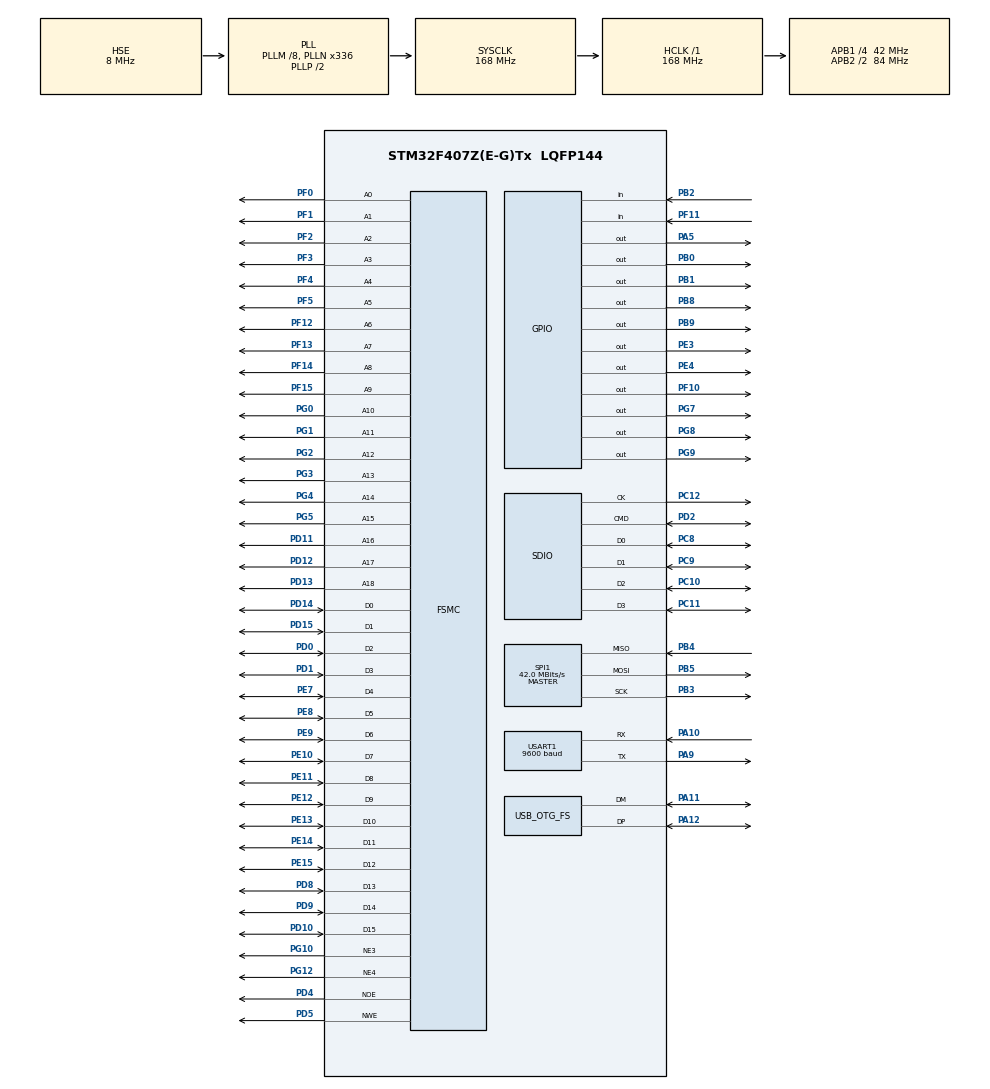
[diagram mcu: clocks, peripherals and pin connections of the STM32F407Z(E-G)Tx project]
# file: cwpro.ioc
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Dma.Request0=SDIO_RX
Dma.Request1=SDIO_TX
Dma.SDIO_RX.0.Direction=DMA_PERIPH_TO_MEMORY
Dma.SDIO_RX.0.FIFOMode=DMA_FIFOMODE_ENABLE
Dma.SDIO_RX.0.FIFOThreshold=DMA_FIFO_THRESHOLD_FULL
Dma.SDIO_RX.0.Instance=DMA2_Stream3
Dma.SDIO_RX.0.MemBurst=DMA_MBURST_INC4
Dma.SDIO_RX.0.MemDataAlignment=DMA_MDATAALIGN_WORD
Dma.SDIO_RX.0.MemInc=DMA_MINC_ENABLE
Dma.SDIO_RX.0.Mode=DMA_PFCTRL
Dma.SDIO_RX.0.PeriphBurst=DMA_PBURST_INC4
Dma.SDIO_RX.0.PeriphDataAlignment=DMA_PDATAALIGN_WORD
Dma.SDIO_RX.0.PeriphInc=DMA_PINC_DISABLE
Dma.SDIO_RX.0.Priority=DMA_PRIORITY_LOW
Dma.SDIO_TX.1.Direction=DMA_MEMORY_TO_PERIPH
Dma.SDIO_TX.1.FIFOMode=DMA_FIFOMODE_ENABLE
Dma.SDIO_TX.1.FIFOThreshold=DMA_FIFO_THRESHOLD_FULL
Dma.SDIO_TX.1.Instance=DMA2_Stream6
Dma.SDIO_TX.1.MemBurst=DMA_MBURST_INC4
Dma.SDIO_TX.1.MemDataAlignment=DMA_MDATAALIGN_WORD
Dma.SDIO_TX.1.MemInc=DMA_MINC_ENABLE
Dma.SDIO_TX.1.Mode=DMA_PFCTRL
Dma.SDIO_TX.1.PeriphBurst=DMA_PBURST_INC4
Dma.SDIO_TX.1.PeriphDataAlignment=DMA_PDATAALIGN_WORD
Dma.SDIO_TX.1.PeriphInc=DMA_PINC_DISABLE
Dma.SDIO_TX.1.Priority=DMA_PRIORITY_LOW
FATFS._CODE_PAGE=936
FATFS._USE_LFN=2
FREERTOS.Queues01=myQueue01,16,uint16_t,0,Dynamic,NULL,NULL
FREERTOS.Tasks01=defaultTask,0,1024,StartDefaultTask,Default,NULL,Dynamic,NULL,NULL;Task_touch,-2,1024,StartTask_touch,Default,NULL,Dynamic,NULL,NULL;Task_main,0,3072,StartTask_main,Default,NULL,Dynamic,NULL,NULL
FREERTOS.configMINIMAL_STACK_SIZE=128
FREERTOS.configTOTAL_HEAP_SIZE=0x5c00
FSMC.AddressSetupTime1=0
FSMC.BusTurnAroundDuration1=0
FSMC.BusTurnAroundDuration2=0
FSMC.DataSetupTime1=0x0b
FSMC.DataSetupTime2=60
FSMC.ExtendedAddressSetupTime2=8
FSMC.ExtendedBusTurnAroundDuration2=0
FSMC.ExtendedDataSetupTime2=7
FSMC.ExtendedMode2=FSMC_EXTENDED_MODE_ENABLE
FSMC.WriteOperation1=FSMC_WRITE_OPERATION_ENABLE
Mcu.Family=STM32F4
Mcu.Name=STM32F407Z(E-G)Tx
Mcu.Package=LQFP144
NVIC.DMA2_Stream3_IRQn=true\:5\:0\:true\:false\:true\:true\:false\:true\:true
NVIC.DMA2_Stream6_IRQn=true\:5\:0\:true\:false\:true\:true\:false\:true\:true
NVIC.HASH_RNG_IRQn=true\:5\:0\:false\:false\:true\:true\:true\:true\:true
NVIC.OTG_FS_IRQn=true\:5\:0\:false\:false\:true\:true\:false\:true\:true
NVIC.PriorityGroup=NVIC_PRIORITYGROUP_4
NVIC.SDIO_IRQn=true\:5\:0\:false\:false\:true\:true\:true\:true\:true
PA10.Mode=Asynchronous
PA10.Signal=USART1_RX
PA11.Mode=Host_Only
PA11.Signal=USB_OTG_FS_DM
PA12.Mode=Host_Only
PA12.Signal=USB_OTG_FS_DP
PA13.Mode=Serial_Wire
PA13.Signal=SYS_JTMS-SWDIO
PA14.Mode=Serial_Wire
PA14.Signal=SYS_JTCK-SWCLK
PA5.GPIO_PuPd=GPIO_PULLUP
PA5.Signal=GPIO_Output
PA9.Mode=Asynchronous
PA9.Signal=USART1_TX
PB0.GPIO_ModeDefaultOutputPP=GPIO_MODE_OUTPUT_PP
PB0.GPIO_PuPd=GPIO_PULLUP
PB0.Signal=GPIO_Output
PB1.GPIO_PuPd=GPIO_PULLUP
PB1.Signal=GPIO_Output
PB2.GPIO_PuPd=GPIO_PULLUP
PB2.Signal=GPIO_Input
PB3.Mode=Full_Duplex_Master
PB3.Signal=SPI1_SCK
PB4.Mode=Full_Duplex_Master
PB4.Signal=SPI1_MISO
PB5.Mode=Full_Duplex_Master
PB5.Signal=SPI1_MOSI
PB8.GPIO_PuPd=GPIO_PULLUP
PB8.Signal=GPIO_Output
PB9.GPIO_PuPd=GPIO_PULLUP
PB9.Signal=GPIO_Output
PC10.GPIO_PuPd=GPIO_PULLUP
PC10.Mode=SD_4_bits_Wide_bus
PC10.Signal=SDIO_D2
PC11.GPIO_PuPd=GPIO_PULLUP
PC11.Mode=SD_4_bits_Wide_bus
PC11.Signal=SDIO_D3
PC12.GPIO_PuPd=GPIO_PULLUP
PC12.Mode=SD_4_bits_Wide_bus
PC12.Signal=SDIO_CK
PC8.GPIO_PuPd=GPIO_PULLUP
PC8.Mode=SD_4_bits_Wide_bus
PC8.Signal=SDIO_D0
PC9.GPIO_PuPd=GPIO_PULLUP
PC9.Mode=SD_4_bits_Wide_bus
PC9.Signal=SDIO_D1
PD0.Signal=FSMC_D2_DA2
PD1.Signal=FSMC_D3_DA3
PD10.Signal=FSMC_D15_DA15
PD11.Signal=FSMC_A16_CLE
PD12.Signal=FSMC_A17_ALE
PD13.Signal=FSMC_A18
PD14.Signal=FSMC_D0_DA0
PD15.Signal=FSMC_D1_DA1
PD2.GPIO_PuPd=GPIO_PULLUP
PD2.Mode=SD_4_bits_Wide_bus
PD2.Signal=SDIO_CMD
PD4.Signal=FSMC_NOE
PD5.Signal=FSMC_NWE
PD8.Signal=FSMC_D13_DA13
PD9.Signal=FSMC_D14_DA14
PE0.Signal=FSMC_NBL0
PE1.Signal=FSMC_NBL1
PE10.Signal=FSMC_D7_DA7
PE11.Signal=FSMC_D8_DA8
PE12.Signal=FSMC_D9_DA9
PE13.Signal=FSMC_D10_DA10
PE14.Signal=FSMC_D11_DA11
PE15.Signal=FSMC_D12_DA12
PE3.GPIO_PuPd=GPIO_PULLUP
PE3.Signal=GPIO_Output
PE4.GPIO_PuPd=GPIO_PULLUP
PE4.Signal=GPIO_Output
PE7.Signal=FSMC_D4_DA4
PE8.Signal=FSMC_D5_DA5
PE9.Signal=FSMC_D6_DA6
PF0.Signal=FSMC_A0
PF1.Signal=FSMC_A1
PF10.GPIO_PuPd=GPIO_PULLUP
PF10.Signal=GPIO_Output
PF11.GPIO_PuPd=GPIO_PULLUP
PF11.Signal=GPIO_Input
PF12.Signal=FSMC_A6
PF13.Signal=FSMC_A7
PF14.Signal=FSMC_A8
PF15.Signal=FSMC_A9
PF2.Signal=FSMC_A2
PF3.Signal=FSMC_A3
PF4.Signal=FSMC_A4
PF5.Signal=FSMC_A5
PG0.Signal=FSMC_A10
PG1.Signal=FSMC_A11
PG10.Mode=NorPsramChipSelect3_1
PG10.Signal=FSMC_NE3
PG12.Mode=NorPsramChipSelect4_2
PG12.Signal=FSMC_NE4
PG2.Signal=FSMC_A12
PG3.Signal=FSMC_A13
PG4.Signal=FSMC_A14
PG5.Signal=FSMC_A15
PG7.GPIO_PuPd=GPIO_PULLUP
PG7.Signal=GPIO_Output
PG8.GPIO_PuPd=GPIO_PULLUP
PG8.Signal=GPIO_Output
PG9.GPIO_PuPd=GPIO_PULLUP
PG9.Signal=GPIO_Output
PH0-OSC_IN.Mode=HSE-External-Oscillator
PH0-OSC_IN.Signal=RCC_OSC_IN
PH1-OSC_OUT.Mode=HSE-External-Oscillator
PH1-OSC_OUT.Signal=RCC_OSC_OUT
ProjectManager.HeapSize=0xf00
ProjectManager.StackSize=0xf00
ProjectManager.TargetToolchain=MDK-ARM V5.32
RCC.48MHZClocksFreq_Value=48000000
RCC.AHBFreq_Value=168000000
RCC.APB1CLKDivider=RCC_HCLK_DIV4
RCC.APB1Freq_Value=42000000
RCC.APB1TimFreq_Value=84000000
RCC.APB2CLKDivider=RCC_HCLK_DIV2
RCC.APB2Freq_Value=84000000
RCC.APB2TimFreq_Value=168000000
RCC.CortexFreq_Value=168000000
RCC.HCLKFreq_Value=168000000
RCC.HSE_VALUE=8000000
RCC.HSI_VALUE=16000000
RCC.LSE_VALUE=32768
RCC.PLLM=8
RCC.PLLN=336
RCC.PLLQ=7
RCC.SYSCLKFreq_VALUE=168000000
RCC.SYSCLKSource=RCC_SYSCLKSOURCE_PLLCLK
RCC.VCOOutputFreq_Value=336000000
SDIO.ClockDiv=4
SH.FSMC_A0.0=FSMC_A0,19b-a1
SH.FSMC_A1.0=FSMC_A1,19b-a1
SH.FSMC_A10.0=FSMC_A10,19b-a1
SH.FSMC_A11.0=FSMC_A11,19b-a1
SH.FSMC_A12.0=FSMC_A12,19b-a1
SH.FSMC_A12.1=FSMC_A12,A12_2
SH.FSMC_A13.0=FSMC_A13,19b-a1
SH.FSMC_A14.0=FSMC_A14,19b-a1
SH.FSMC_A15.0=FSMC_A15,19b-a1
SH.FSMC_A16_CLE.0=FSMC_A16,19b-a1
SH.FSMC_A17_ALE.0=FSMC_A17,19b-a1
SH.FSMC_A18.0=FSMC_A18,19b-a1
SH.FSMC_A2.0=FSMC_A2,19b-a1
SH.FSMC_A3.0=FSMC_A3,19b-a1
SH.FSMC_A4.0=FSMC_A4,19b-a1
SH.FSMC_A5.0=FSMC_A5,19b-a1
SH.FSMC_A6.0=FSMC_A6,19b-a1
SH.FSMC_A7.0=FSMC_A7,19b-a1
SH.FSMC_A8.0=FSMC_A8,19b-a1
SH.FSMC_A9.0=FSMC_A9,19b-a1
SH.FSMC_D0_DA0.0=FSMC_D0,16b-d1
SH.FSMC_D0_DA0.1=FSMC_D0,16b-d2
SH.FSMC_D10_DA10.0=FSMC_D10,16b-d1
SH.FSMC_D10_DA10.1=FSMC_D10,16b-d2
SH.FSMC_D11_DA11.0=FSMC_D11,16b-d1
SH.FSMC_D11_DA11.1=FSMC_D11,16b-d2
SH.FSMC_D12_DA12.0=FSMC_D12,16b-d1
SH.FSMC_D12_DA12.1=FSMC_D12,16b-d2
SH.FSMC_D13_DA13.0=FSMC_D13,16b-d1
SH.FSMC_D13_DA13.1=FSMC_D13,16b-d2
SH.FSMC_D14_DA14.0=FSMC_D14,16b-d1
SH.FSMC_D14_DA14.1=FSMC_D14,16b-d2
SH.FSMC_D15_DA15.0=FSMC_D15,16b-d1
SH.FSMC_D15_DA15.1=FSMC_D15,16b-d2
SH.FSMC_D1_DA1.0=FSMC_D1,16b-d1
SH.FSMC_D1_DA1.1=FSMC_D1,16b-d2
SH.FSMC_D2_DA2.0=FSMC_D2,16b-d1
SH.FSMC_D2_DA2.1=FSMC_D2,16b-d2
SH.FSMC_D3_DA3.0=FSMC_D3,16b-d1
SH.FSMC_D3_DA3.1=FSMC_D3,16b-d2
SH.FSMC_D4_DA4.0=FSMC_D4,16b-d1
SH.FSMC_D4_DA4.1=FSMC_D4,16b-d2
SH.FSMC_D5_DA5.0=FSMC_D5,16b-d1
SH.FSMC_D5_DA5.1=FSMC_D5,16b-d2
SH.FSMC_D6_DA6.0=FSMC_D6,16b-d1
SH.FSMC_D6_DA6.1=FSMC_D6,16b-d2
SH.FSMC_D7_DA7.0=FSMC_D7,16b-d1
SH.FSMC_D7_DA7.1=FSMC_D7,16b-d2
SH.FSMC_D8_DA8.0=FSMC_D8,16b-d1
SH.FSMC_D8_DA8.1=FSMC_D8,16b-d2
SH.FSMC_D9_DA9.0=FSMC_D9,16b-d1
SH.FSMC_D9_DA9.1=FSMC_D9,16b-d2
SH.FSMC_NBL0.0=FSMC_NBL0
SH.FSMC_NBL1.0=FSMC_NBL1
SH.FSMC_NOE.0=FSMC_NOE,Sram1
SH.FSMC_NOE.1=FSMC_NOE,Lcd2
SH.FSMC_NWE.0=FSMC_NWE,Sram1
SH.FSMC_NWE.1=FSMC_NWE,Lcd2
SPI1.CalculateBaudRate=42.0 MBits/s
SPI1.Direction=SPI_DIRECTION_2LINES
SPI1.Mode=SPI_MODE_MASTER
SPI1.VirtualType=VM_MASTER
USART1.BaudRate=9600
USART1.VirtualMode=VM_ASYNC
USB_HOST.USBH_DEBUG_LEVEL-MSC_FS=2
USB_HOST.USBH_HandleTypeDef-MSC_FS=hUsbHostFS
USB_HOST.USBH_PROCESS_STACK_SIZE-MSC_FS=512
USB_HOST.VirtualModeFS=Msc
USB_OTG_FS.VirtualMode=Host_Only
USB_OTG_FS.phy_itface=HCD_PHY_EMBEDDED
VP_CRC_VS_CRC.Mode=CRC_Activate
VP_FATFS_VS_SDIO.Mode=SDIO
VP_FATFS_VS_USB.Mode=USB
VP_FREERTOS_VS_CMSIS_V1.Mode=CMSIS_V1
VP_RNG_VS_RNG.Mode=RNG_Activate
VP_USB_HOST_VS_USB_HOST_MSC_FS.Mode=MSC_FS
board=custom

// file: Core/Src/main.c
/* USER CODE BEGIN Header */
/**
  ******************************************************************************
  * @file           : main.c
  * @brief          : Main program body
  ******************************************************************************
  * @attention
  *
  * Copyright (c) 2023 STMicroelectronics.
  * All rights reserved.
  *
  * This software is licensed under terms that can be found in the LICENSE file
  * in the root directory of this software component.
  * If no LICENSE file comes with this software, it is provided AS-IS.
  *
  ******************************************************************************
  */
/* USER CODE END Header */
#include "main.h"
#include "cmsis_os.h"
#include "crc.h"
#include "dma.h"
#include "fatfs.h"
#include "rng.h"
#include "sdio.h"
#include "spi.h"
#include "usart.h"
#include "usb_host.h"
#include "gpio.h"
#include "fsmc.h"

/* USER CODE BEGIN Includes */
#include "malloc.h"
#include "touch.h"
#include "common.h"

/* USER CODE END Includes */

/* USER CODE BEGIN PV */
 uint32_t g_sys_status = SYS_IDLE;//SYS_IDLE;

 uint32_t g_DiskStatus = NO_DISK_INSERTED;

 uint32_t g_rand[256];
/* USER CODE END PV */

void SystemClock_Config(void);
void MX_FREERTOS_Init(void);

int main(void)
{
  /* USER CODE BEGIN 1 */
    FATFS fsTF;  //TF卡文件系统
	int ret;
  /* USER CODE END 1 */

  /* MCU Configuration--------------------------------------------------------*/

  /* Reset of all peripherals, Initializes the Flash interface and the Systick. */
  HAL_Init();

  /* Configure the system clock */
  SystemClock_Config();

  /* Initialize all configured peripherals */
  MX_GPIO_Init();
  MX_DMA_Init();
  MX_FSMC_Init();
  MX_USART1_UART_Init();
  MX_CRC_Init();
  MX_FATFS_Init();
  MX_SDIO_SD_Init();
  MX_SPI1_Init();
  MX_RNG_Init();
  /* USER CODE BEGIN 2 */
	printf("hello world!!!!\r\n");

 // Memory_Init(INSRAM); 		//初始化内部内存池
 //Memory_Init(EXSRAM);  	//初始化外部内存池
 //  ret = f_mount(&fsTF,"0:",1); 		//挂载TF卡
	//printf("hello Memory_Init succ!!!! ret=%d\r\n",ret);
  /* USER CODE END 2 */

  /* Call init function for freertos objects (in freertos.c) */
  MX_FREERTOS_Init();

  /* Start scheduler */
  osKernelStart();

  /* We should never get here as control is now taken by the scheduler */
  /* Infinite loop */
  while (1)
  {

  }
}

void SystemClock_Config(void)
{
  RCC_OscInitTypeDef RCC_OscInitStruct = {0};
  RCC_ClkInitTypeDef RCC_ClkInitStruct = {0};

  /** Configure the main internal regulator output voltage
  */
  __HAL_RCC_PWR_CLK_ENABLE();
  __HAL_PWR_VOLTAGESCALING_CONFIG(PWR_REGULATOR_VOLTAGE_SCALE1);

  /** Initializes the RCC Oscillators according to the specified parameters
  * in the RCC_OscInitTypeDef structure.
  */
  RCC_OscInitStruct.OscillatorType = RCC_OSCILLATORTYPE_HSE;
  RCC_OscInitStruct.HSEState = RCC_HSE_ON;
  RCC_OscInitStruct.PLL.PLLState = RCC_PLL_ON;
  RCC_OscInitStruct.PLL.PLLSource = RCC_PLLSOURCE_HSE;
  RCC_OscInitStruct.PLL.PLLM = 8;
  RCC_OscInitStruct.PLL.PLLN = 336;
  RCC_OscInitStruct.PLL.PLLP = RCC_PLLP_DIV2;
  RCC_OscInitStruct.PLL.PLLQ = 7;
  if (HAL_RCC_OscConfig(&RCC_OscInitStruct) != HAL_OK)
  {
    Error_Handler();
  }

  /** Initializes the CPU, AHB and APB buses clocks
  */
  RCC_ClkInitStruct.ClockType = RCC_CLOCKTYPE_HCLK|RCC_CLOCKTYPE_SYSCLK
                              |RCC_CLOCKTYPE_PCLK1|RCC_CLOCKTYPE_PCLK2;
  RCC_ClkInitStruct.SYSCLKSource = RCC_SYSCLKSOURCE_PLLCLK;
  RCC_ClkInitStruct.AHBCLKDivider = RCC_SYSCLK_DIV1;
  RCC_ClkInitStruct.APB1CLKDivider = RCC_HCLK_DIV4;
  RCC_ClkInitStruct.APB2CLKDivider = RCC_HCLK_DIV2;

  if (HAL_RCC_ClockConfig(&RCC_ClkInitStruct, FLASH_LATENCY_5) != HAL_OK)
  {
    Error_Handler();
  }
}

/* USER CODE BEGIN 4 */
int fputc(int ch,FILE *stream)
{
	HAL_UART_Transmit(&huart1, (uint8_t*)&ch, 1, HAL_MAX_DELAY);
	return 0;
}

/* USER CODE END 4 */

void Error_Handler(void)
{
  __disable_irq();
  while (1)
  {
  }
}

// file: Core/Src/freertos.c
/* USER CODE BEGIN Header */
/**
  ******************************************************************************
  * File Name          : freertos.c
  * Description        : Code for freertos applications
  ******************************************************************************
  * @attention
  *
  * Copyright (c) 2024 STMicroelectronics.
  * All rights reserved.
  *
  * This software is licensed under terms that can be found in the LICENSE file
  * in the root directory of this software component.
  * If no LICENSE file comes with this software, it is provided AS-IS.
  *
  ******************************************************************************
  */
/* USER CODE END Header */

#include "FreeRTOS.h"
#include "task.h"
#include "main.h"
#include "cmsis_os.h"

/* USER CODE BEGIN Includes */
#include "stdio.h"
#include "string.h"
#include "usart.h"
#include "key_led.h"
#include "my_lcd.h"
#include "touch.h"
#include "xpt2046.h"
#include "GUI.h"
#include "MainDLG.h"
#include "24c02.h"
#include "ff.h"
#include "my_png.h"
#include "SelectImgWin.h"
#include "enterImgPwd.h"
#include "resultDLG.h"
#include "rng.h"
//#include "enterImgPwd.h"

//#include "FramewinDLG.h"

//#include "emwin_demo.h"

/* USER CODE END Includes */

/* USER CODE BEGIN PTD */
FATFS fsTF;  //TF卡文件系统

void lcdbenin(void);
void emwin_main(void);
/* USER CODE END PTD */

osThreadId defaultTaskHandle;
osThreadId Task_touchHandle;
osThreadId Task_mainHandle;
osMessageQId myQueue01Handle;

void StartDefaultTask(void const * argument);
void StartTask_touch(void const * argument);
void StartTask_main(void const * argument);

extern void MX_USB_HOST_Init(void);
void MX_FREERTOS_Init(void); /* (MISRA C 2004 rule 8.1) */

/* GetIdleTaskMemory prototype (linked to static allocation support) */
void vApplicationGetIdleTaskMemory( StaticTask_t **ppxIdleTaskTCBBuffer, StackType_t **ppxIdleTaskStackBuffer, uint32_t *pulIdleTaskStackSize );

/* USER CODE BEGIN GET_IDLE_TASK_MEMORY */
static StaticTask_t xIdleTaskTCBBuffer;
static StackType_t xIdleStack[configMINIMAL_STACK_SIZE];

void vApplicationGetIdleTaskMemory( StaticTask_t **ppxIdleTaskTCBBuffer, StackType_t **ppxIdleTaskStackBuffer, uint32_t *pulIdleTaskStackSize )
{
  *ppxIdleTaskTCBBuffer = &xIdleTaskTCBBuffer;
  *ppxIdleTaskStackBuffer = &xIdleStack[0];
  *pulIdleTaskStackSize = configMINIMAL_STACK_SIZE;
  /* place for user code */
}
/* USER CODE END GET_IDLE_TASK_MEMORY */

void MX_FREERTOS_Init(void) {

  /* Create the queue(s) */
  /* definition and creation of myQueue01 */
  osMessageQDef(myQueue01, 16, uint16_t);
  myQueue01Handle = osMessageCreate(osMessageQ(myQueue01), NULL);

  /* Create the thread(s) */
  /* definition and creation of defaultTask */
  osThreadDef(defaultTask, StartDefaultTask, osPriorityNormal, 0, 1024);
  defaultTaskHandle = osThreadCreate(osThread(defaultTask), NULL);

  /* definition and creation of Task_touch */
  osThreadDef(Task_touch, StartTask_touch, osPriorityLow, 0, 1024);
  Task_touchHandle = osThreadCreate(osThread(Task_touch), NULL);

  /* definition and creation of Task_main */
  osThreadDef(Task_main, StartTask_main, osPriorityNormal, 0, 3072);
  Task_mainHandle = osThreadCreate(osThread(Task_main), NULL);

}

void StartDefaultTask(void const * argument)
{
  /* init code for USB_HOST */
  MX_USB_HOST_Init();
  /* USER CODE BEGIN StartDefaultTask */
  uint32_t rng_val = 0;
  /* Infinite loop */
  for(;;)
  {

		osDelay(2000);
 //   GUI_Delay(1000);
//		AT24C02_Read(0,(uint8_t *)xx,sizeof(xx));
		rng_val = HAL_RNG_GetRandomNumber(&hrng);
	//	printf("yyyyyyyyyyyyyyyyyy rng_val=%x\r\n",rng_val);

//		if(g_sys_status==SYS_CREATE_WALLET)

//			emwin_main();

  }
  /* USER CODE END StartDefaultTask */
}

void StartTask_touch(void const * argument)
{
  /* USER CODE BEGIN StartTask_touch */
	int i=0;
   uint16_t xx=0;
	uint16_t yy=0;
		Touch_Init();
	//    WM_MESSAGE message;

	printf("000StartTask02 StartTask02\r\n");
  //  GUI_CURSOR_Show();

  /* Infinite loop */
  for(;;)
  {
  //    xx = RTouch_Read_XorY(0xD0);
	//    yy = RTouch_Read_XorY(0x90);
	//	  printf("RTouch_Read_XorY  xx=%d  yy=%d\r\n",xx,yy);
		    i++;
		   if(i==1000)
			 {
				 i=0;
  //  message.MsgId = MSG_CUSTOM;
				 printf("StartTask02 StartTask02 \r\n");
			//	 WM_SendMessage(g_hWin, &message);

			 }
        GUI_TOUCH_Exec();
		  	//	osDelay(5);
        GUI_Delay(5);
  }
  /* USER CODE END StartTask_touch */
}

void StartTask_main(void const * argument)
{
  /* USER CODE BEGIN StartTask_main */
		int ret=0xff;

	char xx[]="abcdef";
		LCD_Init();
  //	lcdbenin();
	  GUI_Init();
	  LED1(1);
	  LED2(1);
		LED3(1);
	  printf("GUI_Init succ!!!\r\n");

/*	GUI_SetBkColor(GUI_BLUE); //设置背景颜色
  GUI_SetColor(GUI_YELLOW); //设置颜色
  GUI_Clear(); //清屏
  GUI_SetFont(&GUI_Font24_ASCII); //设置字体
   GUI_DispStringAt("Hello Word!",0,0); */
//emwin_main();
  // GUIDEMO_Main();

//	GUIDEMO_Automotive();
//	AT24C02_Write(0,(uint8_t *)xx,sizeof(xx));
//	printf("111yyyyyyyyyyyyyyy\r\n");
	//printf("AT24C02_Read xx=%s \r\n",xx);
 //  emwin_main();
  //CreateMain();

//   Fatfs_RW_test();

	//CreateFramewin();
	//osDelay(2000);

		BSP_SD_Init();
	  osDelay(30);
//	while(ret!=0)
	{
    ret = f_mount(&fsTF,"0:",1); 		//挂载TF卡
		osDelay(50);
	}
//		osDelay(50);
	  printf("\r\n Mounting the TF card successfully. ret=%d\r\n",(int)ret);
	  main_menu();
//	CreateMain();
  // emwin_main();
  // emwin_main();
	  osEvent event;
	uint32_t msg;

  /* Infinite loop */
  for(;;)
  {
		event = osMessageGet(myQueue01Handle, osWaitForever);
    if (event.status == osEventMessage)
    {
			msg=event.value.v;
			printf("rev msg = %d \r\n",msg);
			if(msg==MSG_CREATE_WALLET)
			   invokeSeleImgWin();
			else if(msg==MSG_RETURN_MAIN)
			{
				main_menu();
			}
			else if(msg==MSG_SETCW_PWD)
			{

				enter_ImgPwdPad();
				//enter_ImgPwdPad();
			}
			else if(msg==MSG_CW_RESULT)
			{
				CreateResDlg();

			}
				else if(msg==MSG_SHOW_QRCODE)
			{
				CreateResDlg();

			}
   //   USBH_Process((USBH_HandleTypeDef *)argument);
    }
  }
  /* USER CODE END StartTask_main */
}

/* USER CODE BEGIN Application */
void lcdbenin(void)
{

	BRUSH_COLOR=RED;      //设置画笔颜色为红色
	LCD_DisplayString(0,10,16,BLACK,"Welcome to use secure wallet");//
	LCD_DisplayString(20,50,16,BLUE,"Create wallet");
	LCD_DisplayString(20,90,16,BLUE,"View wallet");
	LCD_DisplayString(20,130,16,RED,"Decrypt wallet");

  LCD_DisplayString(lcd_width-40,lcd_height-18,16,RED,"OK");//显示清屏区域

//	LCD_DisplayString(50,130,16,"KEY1:Number Test");
//	- Create wallet
//- View wallet
//- Decrypt wallet
}

/* USER CODE END Application */
